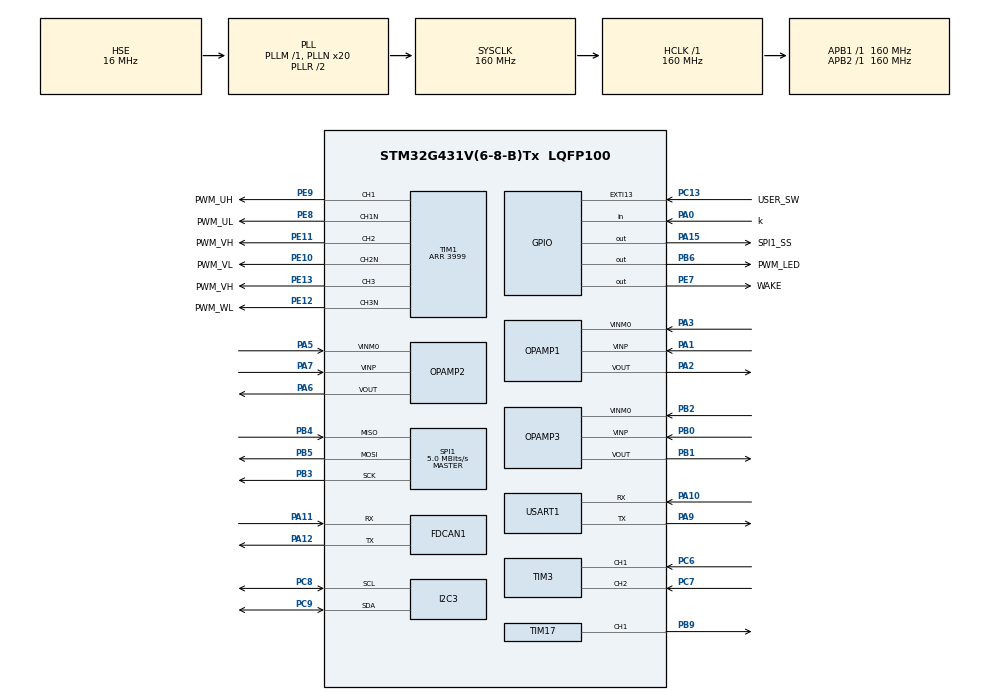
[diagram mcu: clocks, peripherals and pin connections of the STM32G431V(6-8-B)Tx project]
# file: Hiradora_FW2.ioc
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ADC1.ContinuousConvMode=ENABLE
ADC1.EnableInjectedConversion=ENABLE
ADC1.EnableRegularConversion=DISABLE
ADC1.ExternalTrigInjecConv=ADC_EXTERNALTRIGINJEC_T1_TRGO
ADC1.InjNumberOfConversion=3
ADC1.InjectedChannel-10\#ChannelInjectedConversion=ADC_CHANNEL_VREFINT
ADC1.InjectedChannel-6\#ChannelInjectedConversion=ADC_CHANNEL_3
ADC1.InjectedChannel-7\#ChannelInjectedConversion=ADC_CHANNEL_12
ADC1.InjectedOffsetNumber-10\#ChannelInjectedConversion=ADC_OFFSET_NONE
ADC1.InjectedOffsetNumber-6\#ChannelInjectedConversion=ADC_OFFSET_NONE
ADC1.InjectedOffsetNumber-7\#ChannelInjectedConversion=ADC_OFFSET_NONE
ADC1.InjectedRank-10\#ChannelInjectedConversion=3
ADC1.InjectedRank-6\#ChannelInjectedConversion=1
ADC1.InjectedRank-7\#ChannelInjectedConversion=2
ADC1.InjectedSamplingTime-10\#ChannelInjectedConversion=ADC_SAMPLETIME_2CYCLES_5
ADC1.InjectedSamplingTime-6\#ChannelInjectedConversion=ADC_SAMPLETIME_2CYCLES_5
ADC1.InjectedSamplingTime-7\#ChannelInjectedConversion=ADC_SAMPLETIME_2CYCLES_5
ADC1.Mode=ADC_DUALMODE_INJECSIMULT
ADC1.Rank1_Channel=ADC_CHANNEL_3
ADC1.Rank2_Channel=ADC_CHANNEL_12
ADC1.Rank3_Channel=ADC_CHANNEL_VREFINT
ADC1.master=1
ADC2.EnableInjectedConversion=ENABLE
ADC2.EnableRegularConversion=DISABLE
ADC2.InjNumberOfConversion=1
ADC2.InjectedChannel-19\#ChannelInjectedConversion=ADC_CHANNEL_3
ADC2.InjectedOffsetNumber-19\#ChannelInjectedConversion=ADC_OFFSET_NONE
ADC2.InjectedRank-19\#ChannelInjectedConversion=1
ADC2.InjectedSamplingTime-19\#ChannelInjectedConversion=ADC_SAMPLETIME_2CYCLES_5
ADC2.Mode=ADC_DUALMODE_INJECSIMULT
ADC2.Rank1_Channel=ADC_CHANNEL_3
Dma.Request0=SPI1_RX
Dma.SPI1_RX.0.Direction=DMA_PERIPH_TO_MEMORY
Dma.SPI1_RX.0.EventEnable=DISABLE
Dma.SPI1_RX.0.Instance=DMA1_Channel2
Dma.SPI1_RX.0.MemDataAlignment=DMA_MDATAALIGN_HALFWORD
Dma.SPI1_RX.0.MemInc=DMA_MINC_ENABLE
Dma.SPI1_RX.0.Mode=DMA_NORMAL
Dma.SPI1_RX.0.PeriphDataAlignment=DMA_PDATAALIGN_HALFWORD
Dma.SPI1_RX.0.PeriphInc=DMA_PINC_DISABLE
Dma.SPI1_RX.0.Polarity=HAL_DMAMUX_REQ_GEN_RISING
Dma.SPI1_RX.0.Priority=DMA_PRIORITY_VERY_HIGH
Dma.SPI1_RX.0.RequestNumber=1
Dma.SPI1_RX.0.SignalID=NONE
Dma.SPI1_RX.0.SyncEnable=DISABLE
Dma.SPI1_RX.0.SyncPolarity=HAL_DMAMUX_SYNC_NO_EVENT
Dma.SPI1_RX.0.SyncRequestNumber=1
Dma.SPI1_RX.0.SyncSignalID=NONE
FDCAN1.CalculateBaudRateNominal=1000000
FDCAN1.CalculateTimeBitNominal=1000
FDCAN1.CalculateTimeQuantumNominal=50.0
FDCAN1.DataPrescaler=2
FDCAN1.DataTimeSeg1=15
FDCAN1.DataTimeSeg2=4
FDCAN1.FrameFormat=FDCAN_FRAME_CLASSIC
FDCAN1.NominalPrescaler=8
FDCAN1.NominalTimeSeg1=15
FDCAN1.NominalTimeSeg2=4
FDCAN1.StdFiltersNbr=1
I2C3.Timing=0x30D29DE4
Mcu.Family=STM32G4
Mcu.Name=STM32G431V(6-8-B)Tx
Mcu.Package=LQFP100
NVIC.ADC1_2_IRQn=true\:0\:0\:true\:false\:true\:true\:true\:true
NVIC.DMA1_Channel2_IRQn=true\:0\:0\:false\:false\:true\:false\:true\:true
NVIC.EXTI15_10_IRQn=true\:0\:0\:false\:false\:true\:true\:true\:true
NVIC.FDCAN1_IT0_IRQn=true\:0\:0\:false\:false\:true\:true\:true\:true
NVIC.FDCAN1_IT1_IRQn=true\:0\:0\:false\:false\:true\:true\:true\:true
NVIC.PriorityGroup=NVIC_PRIORITYGROUP_4
NVIC.SPI1_IRQn=true\:0\:0\:false\:false\:true\:true\:true\:true
NVIC.TIM1_TRG_COM_TIM17_IRQn=true\:0\:0\:false\:false\:true\:true\:true\:true
NVIC.TIM1_UP_TIM16_IRQn=true\:0\:0\:true\:false\:true\:true\:true\:true
NVIC.TIM2_IRQn=true\:0\:0\:false\:false\:true\:true\:true\:true
NVIC.TIM3_IRQn=true\:0\:0\:false\:false\:true\:true\:true\:true
OPAMP1.PgaGain=OPAMP_PGA_GAIN_16_OR_MINUS_15
OPAMP1.PowerMode=OPAMP_POWERMODE_NORMALSPEED
OPAMP2.PgaGain=OPAMP_PGA_GAIN_16_OR_MINUS_15
OPAMP2.PowerMode=OPAMP_POWERMODE_NORMALSPEED
OPAMP3.PgaGain=OPAMP_PGA_GAIN_16_OR_MINUS_15
OPAMP3.PowerMode=OPAMP_POWERMODE_NORMALSPEED
PA0.GPIO_Label=k
PA0.Signal=GPIO_Input
PA1.Mode=PGA Connected-INVERTINGINPUT_IO0_BIAS
PA1.Signal=OPAMP1_VINP
PA10.Mode=Asynchronous
PA10.Signal=USART1_RX
PA11.Mode=FDCAN_Activate
PA11.Signal=FDCAN1_RX
PA12.Mode=FDCAN_Activate
PA12.Signal=FDCAN1_TX
PA15.GPIO_Label=SPI1_SS
PA15.GPIO_Speed=GPIO_SPEED_FREQ_VERY_HIGH
PA15.Signal=GPIO_Output
PA2.Signal=SharedAnalog_PA2
PA3.Mode=PGA Connected-INVERTINGINPUT_IO0_BIAS
PA3.Signal=OPAMP1_VINM0
PA5.Mode=PGA Connected-INVERTINGINPUT_IO0_BIAS
PA5.Signal=OPAMP2_VINM0
PA6.Signal=SharedAnalog_PA6
PA7.Mode=PGA Connected-INVERTINGINPUT_IO0_BIAS
PA7.Signal=OPAMP2_VINP
PA9.Mode=Asynchronous
PA9.Signal=USART1_TX
PB0.Mode=PGA Connected-INVERTINGINPUT_IO0_BIAS
PB0.Signal=OPAMP3_VINP
PB1.Signal=SharedAnalog_PB1
PB2.Mode=PGA Connected-INVERTINGINPUT_IO0_BIAS
PB2.Signal=OPAMP3_VINM0
PB3.Mode=Full_Duplex_Master
PB3.Signal=SPI1_SCK
PB4.Mode=Full_Duplex_Master
PB4.Signal=SPI1_MISO
PB5.Mode=Full_Duplex_Master
PB5.Signal=SPI1_MOSI
PB6.GPIO_Label=PWM_LED
PB6.Signal=GPIO_Output
PB9.Signal=S_TIM17_CH1
PC13.GPIO_Label=USER_SW
PC13.GPIO_ModeDefaultEXTI=GPIO_MODE_IT_FALLING
PC13.Signal=GPXTI13
PC6.Signal=S_TIM3_CH1
PC7.Signal=S_TIM3_CH2
PC8.Mode=I2C
PC8.Signal=I2C3_SCL
PC9.Mode=I2C
PC9.Signal=I2C3_SDA
PE10.GPIO_Label=PWM_VL
PE10.Mode=PWM Generation2 CH2 CH2N
PE10.Signal=TIM1_CH2N
PE11.GPIO_Label=PWM_VH
PE11.Signal=S_TIM1_CH2
PE12.GPIO_Label=PWM_WL
PE12.Mode=PWM Generation3 CH3 CH3N
PE12.Signal=TIM1_CH3N
PE13.GPIO_Label=PWM_VH
PE13.Signal=S_TIM1_CH3
PE7.GPIO_Label=WAKE
PE7.Signal=GPIO_Output
PE8.GPIO_Label=PWM_UL
PE8.Mode=PWM Generation1 CH1 CH1N
PE8.Signal=TIM1_CH1N
PE9.GPIO_Label=PWM_UH
PE9.Signal=S_TIM1_CH1
PF0-OSC_IN.Mode=HSE-External-Oscillator
PF0-OSC_IN.Signal=RCC_OSC_IN
PF1-OSC_OUT.Mode=HSE-External-Oscillator
PF1-OSC_OUT.Signal=RCC_OSC_OUT
ProjectManager.HeapSize=0x200
ProjectManager.StackSize=0xc00
ProjectManager.TargetToolchain=CMake
RCC.ADC12Freq_Value=160000000
RCC.AHBFreq_Value=160000000
RCC.APB1Freq_Value=160000000
RCC.APB1TimFreq_Value=160000000
RCC.APB2Freq_Value=160000000
RCC.APB2TimFreq_Value=160000000
RCC.CortexFreq_Value=160000000
RCC.EXTERNAL_CLOCK_VALUE=12288000
RCC.HCLKFreq_Value=160000000
RCC.HSE_VALUE=16000000
RCC.HSI48_VALUE=48000000
RCC.HSI_VALUE=16000000
RCC.LSE_VALUE=32768
RCC.PLLN=20
RCC.PLLSourceVirtual=RCC_PLLSOURCE_HSE
RCC.SYSCLKFreq_VALUE=160000000
RCC.SYSCLKSource=RCC_SYSCLKSOURCE_PLLCLK
RCC.USBFreq_Value=160000000
RCC.VCOOutputFreq_Value=320000000
SH.S_TIM17_CH1.0=TIM17_CH1,PWM Generation1 CH1
SH.S_TIM1_CH1.0=TIM1_CH1,PWM Generation1 CH1 CH1N
SH.S_TIM1_CH2.0=TIM1_CH2,PWM Generation2 CH2 CH2N
SH.S_TIM1_CH3.0=TIM1_CH3,PWM Generation3 CH3 CH3N
SH.S_TIM3_CH1.0=TIM3_CH1,Encoder_Interface
SH.S_TIM3_CH2.0=TIM3_CH2,Encoder_Interface
SH.SharedAnalog_PA2.0=OPAMP1_VOUT,PGA Connected-INVERTINGINPUT_IO0_BIAS
SH.SharedAnalog_PA2.1=ADC1_IN3,IN3-Single-Ended
SH.SharedAnalog_PA6.0=OPAMP2_VOUT,PGA Connected-INVERTINGINPUT_IO0_BIAS
SH.SharedAnalog_PA6.1=ADC2_IN3,IN3-Single-Ended
SH.SharedAnalog_PB1.0=OPAMP3_VOUT,PGA Connected-INVERTINGINPUT_IO0_BIAS
SH.SharedAnalog_PB1.1=ADC1_IN12,IN12-Single-Ended
SPI1.BaudRatePrescaler=SPI_BAUDRATEPRESCALER_32
SPI1.CLKPhase=SPI_PHASE_2EDGE
SPI1.CalculateBaudRate=5.0 MBits/s
SPI1.DataSize=SPI_DATASIZE_16BIT
SPI1.Direction=SPI_DIRECTION_2LINES
SPI1.Mode=SPI_MODE_MASTER
SPI1.VirtualType=VM_MASTER
TIM1.AutoReloadPreload=TIM_AUTORELOAD_PRELOAD_ENABLE
TIM1.Channel-PWM\ Generation1\ CH1\ CH1N=TIM_CHANNEL_1
TIM1.Channel-PWM\ Generation2\ CH2\ CH2N=TIM_CHANNEL_2
TIM1.Channel-PWM\ Generation3\ CH3\ CH3N=TIM_CHANNEL_3
TIM1.CounterMode=TIM_COUNTERMODE_CENTERALIGNED3
TIM1.DeadTime=100
TIM1.DeadTimePreload=DISABLE
TIM1.OCFastMode_PWM-PWM\ Generation1\ CH1\ CH1N=TIM_OCFAST_DISABLE
TIM1.OCFastMode_PWM-PWM\ Generation2\ CH2\ CH2N=TIM_OCFAST_DISABLE
TIM1.OCFastMode_PWM-PWM\ Generation3\ CH3\ CH3N=TIM_OCFAST_DISABLE
TIM1.OCMode_PWM-PWM\ Generation1\ CH1\ CH1N=TIM_OCMODE_PWM2
TIM1.OCMode_PWM-PWM\ Generation2\ CH2\ CH2N=TIM_OCMODE_PWM2
TIM1.OCMode_PWM-PWM\ Generation3\ CH3\ CH3N=TIM_OCMODE_PWM2
TIM1.PeriodNoDither=3999
TIM1.RepetitionCounter=1
TIM1.TIM_MasterOutputTrigger=TIM_TRGO_UPDATE
TIM16.PeriodNoDither=15999
TIM16.Prescaler=99
TIM17.Channel=TIM_CHANNEL_1
TIM17.Prescaler=159
TIM2.PeriodNoDither=199
TIM2.Prescaler=159
TIM3.EncoderMode=TIM_ENCODERMODE_TI12
TIM8.PeriodNoDither=64
USART1.VirtualMode-Asynchronous=VM_ASYNC
VP_ADC1_Vref_Input.Mode=IN-Vrefint
VP_SYS_VS_DBSignals.Mode=DisableDeadBatterySignals
VP_TIM16_VS_ClockSourceINT.Mode=Enable_Timer
VP_TIM17_VS_ClockSourceINT.Mode=Enable_Timer
VP_TIM1_VS_ClockSourceINT.Mode=Internal
VP_TIM2_VS_ClockSourceINT.Mode=Internal
VP_TIM8_VS_ClockSourceINT.Mode=Internal
VP_TIM8_VS_OPM.Mode=OPM_bit
board=custom

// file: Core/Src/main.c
/* USER CODE BEGIN Header */
/**
  ******************************************************************************
  * @file           : main.c
  * @brief          : Main program body
  ******************************************************************************
  * @attention
  *
  * Copyright (c) 2026 STMicroelectronics.
  * All rights reserved.
  *
  * This software is licensed under terms that can be found in the LICENSE file
  * in the root directory of this software component.
  * If no LICENSE file comes \with this software, it is provided AS-IS.
  *
  ******************************************************************************
  */
/* USER CODE END Header */
#include "main.h"

/* USER CODE BEGIN Includes */
#include <stdint.h>
#include <stdio.h>
#include <string.h>
#include <math.h>
#include <stdlib.h>
/* USER CODE END Includes */

/* USER CODE BEGIN PTD */
typedef struct {
    volatile float speed;
    float p,i,d;
    volatile float speed_target;
    volatile float now_speed_target;
    volatile float different_sum;
    volatile float low_pass_different_sum;
    volatile float last_difference;
    volatile float last_input;
    volatile float low_pass_derivative;
    volatile float last_last_difference;
    volatile float current_d;
    volatile float current_p;
    volatile float current_d_target;
    volatile float current_p_target;
    volatile float current_d_different_sum;
    volatile float current_d_low_pass_different_sum;
    volatile float current_d_last_difference;      //currentは電流といういみ　現在ではない
    volatile float current_p_different_sum;
    volatile float current_p_low_pass_different_sum;
    volatile float current_p_last_difference;
    volatile float current_d_pgain;
    volatile float current_d_igain;
    volatile float current_d_dgain;
    volatile float current_p_pgain;
    volatile float current_p_igain;
    volatile float current_p_dgain;
}pid_items;

pid_items motor[3];

volatile int cutoff;
/* USER CODE END PTD */

/* USER CODE BEGIN PD */
#define CALIB_FLASH_ADDR   0x0801F800u
#define CALIB_MAGIC        0xCA11B0A1u

typedef struct __attribute__((packed)) {
    uint32_t magic;
    float    zero_offset_rad;
    uint32_t crc;
} calib_data_t;
/* USER CODE END PD */

ADC_HandleTypeDef hadc1;
ADC_HandleTypeDef hadc2;

FDCAN_HandleTypeDef hfdcan1;

I2C_HandleTypeDef hi2c3;

OPAMP_HandleTypeDef hopamp1;
OPAMP_HandleTypeDef hopamp2;
OPAMP_HandleTypeDef hopamp3;

SPI_HandleTypeDef hspi1;
DMA_HandleTypeDef hdma_spi1_rx;

TIM_HandleTypeDef htim1;
TIM_HandleTypeDef htim2;
TIM_HandleTypeDef htim3;
TIM_HandleTypeDef htim8;
TIM_HandleTypeDef htim16;
TIM_HandleTypeDef htim17;

UART_HandleTypeDef huart1;

/* USER CODE BEGIN PV */

#define STSPIN_I2C_ADDR   (0x47 << 1)   // I2Cのスレーブアドレスには7bitアドレスと8bitアドレスがあり、アドレスの後ろに読み込みか書き込みかを示す1bit（R/Wビット）がくっついて送信される。

static HAL_StatusTypeDef stspin_write_reg(uint8_t reg, uint8_t val)
{
    return HAL_I2C_Mem_Write(&hi2c3, STSPIN_I2C_ADDR, reg,
                              I2C_MEMADD_SIZE_8BIT, &val, 1, 100);
}

static HAL_StatusTypeDef stspin_read_reg(uint8_t reg, uint8_t *val)
{
    return HAL_I2C_Mem_Read(&hi2c3, STSPIN_I2C_ADDR, reg,
                             I2C_MEMADD_SIZE_8BIT, val, 1, 100);
}

// STATUSレジスタ(0x80)を読み、フォルトがあればCLEAR(0x09)に0xFFを書く
static uint8_t stspin_clear_faults(void)
{
    uint8_t status = 0;
    stspin_read_reg(0x80, &status);
    if (status & 0x0F) {          // もしstatusの下位4bitの中に1があり、エラーがある場合はifが通る
        stspin_write_reg(0x09, 0xFF);  // CLEARレジスタ
    }
    return status;
}

#define PWM_PERIOD 3999      //カウンターがどこまで数えたら 0 に戻るかを決める天井の数値
#define POLE_PAIRS 7         //モーターの外側についている磁石の数
#define clock_time 0.0002    //time一回当たりの周期
#define resistance_for_current 0.001   //電流計測に用いる抵抗値
#define opamp_gain 16.0  //cudemxで設定したPGAgainの値
#define MAX_PHASE_CURRENT_A   7.0f
#define drive_voltage 3.3  //マイコンの駆動電圧
static inline float fast_sin(float x) { return sinf(x); }
static inline float fast_cos(float x) { return cosf(x); }

volatile int pid_mode[3] = {0, 0, 0};   //0ならlocate_pid 1ならspeed_pid
volatile int control_motor_mode[3] = {0, 0, 0};       //モーターの制御モード

volatile uint32_t rx_ok_count = 0;
static volatile uint32_t tim2_cnt = 0;

/*電流値　単位はアンペア*/
volatile float current_u = 0.0f;
volatile float current_v = 0.0f;
volatile float current_w = 0.0f;
volatile uint8_t overcurrent_fault = 0;

//現在の速度を計算する？ための関数
volatile float speed_now = 0;

/*実際にADCで読み取った値*/
uint32_t offset_u = 2048;
uint32_t offset_v = 2048;
uint32_t offset_w = 2048;

#define CAN_MOTOR_CMD_BASE_ID  0x303u
#define CAN_MOTOR_NUM          3u

typedef struct __attribute__((packed)) {
    float   speed_target;         /* byte0-3 */
    uint8_t pid_mode;             /* byte4: 0=locate_pid, 1=speed_pid */
    uint8_t control_motor_mode;   /* byte5: 0=電圧制御, 1=電流制御 */
    uint8_t reserved[2];          /* byte6-7 */
} can_motor_cmd_t;

/* USER CODE END PV */

void SystemClock_Config(void);
static void MX_GPIO_Init(void);
static void MX_DMA_Init(void);
static void MX_TIM1_Init(void);
static void MX_FDCAN1_Init(void);
static void MX_SPI1_Init(void);
static void MX_TIM17_Init(void);
static void MX_USART1_UART_Init(void);
static void MX_I2C3_Init(void);
static void MX_TIM2_Init(void);
static void MX_TIM16_Init(void);
static void MX_ADC1_Init(void);
static void MX_ADC2_Init(void);
static void MX_OPAMP1_Init(void);
static void MX_OPAMP2_Init(void);
static void MX_OPAMP3_Init(void);
static void MX_TIM8_Init(void);
static void MX_TIM3_Init(void);
/* USER CODE BEGIN PFP */
float locate_pid(volatile float output, float target, float p, float i, float d,volatile float *different_sum, volatile float *low_pass_different_sum,volatile float *last_difference, int cutoff);
float speed_pid(volatile float output, float target, float p, float i, float d, volatile float *low_pass_different_sum, volatile float *last_difference, volatile float *last_last_difference, volatile float last_input, volatile float *low_pass_derivative, int cutoff);
void measure_current(void);
static void FDCAN1_ConfigFilterAndStart(void);
static int calib_load(float *zero_offset_rad_out);
static HAL_StatusTypeDef calib_save(float zero_offset_rad_val);
/* USER CODE END PFP */

/* USER CODE BEGIN 0 */

static void FDCAN1_ConfigFilterAndStart(void)
{
    FDCAN_FilterTypeDef sFilterConfig;

    /* 0x301〜0x303 の標準IDだけをRXFIFO0に通す */
    sFilterConfig.IdType       = FDCAN_STANDARD_ID;
    sFilterConfig.FilterIndex  = 0;
    sFilterConfig.FilterType   = FDCAN_FILTER_DUAL;
    sFilterConfig.FilterConfig = FDCAN_FILTER_TO_RXFIFO0;
    sFilterConfig.FilterID1    = CAN_MOTOR_CMD_BASE_ID;
    sFilterConfig.FilterID2    = CAN_MOTOR_CMD_BASE_ID;
    if (HAL_FDCAN_ConfigFilter(&hfdcan1, &sFilterConfig) != HAL_OK)
    {
        Error_Handler();
    }

    /* フィルタに合致しないフレームは破棄、リモートフレームも破棄 */
    if (HAL_FDCAN_ConfigGlobalFilter(&hfdcan1, FDCAN_REJECT, FDCAN_REJECT,
                                      FDCAN_FILTER_REMOTE, FDCAN_FILTER_REMOTE) != HAL_OK)
    {
        Error_Handler();
    }

    if (HAL_FDCAN_ActivateNotification(&hfdcan1, FDCAN_IT_RX_FIFO0_NEW_MESSAGE, 0) != HAL_OK)
    {
        Error_Handler();
    }

    if (HAL_FDCAN_Start(&hfdcan1) != HAL_OK)
    {
        Error_Handler();
    }
}

void HAL_FDCAN_RxFifo0Callback(FDCAN_HandleTypeDef *hfdcan, uint32_t RxFifo0ITs)
{
    if ((RxFifo0ITs & FDCAN_IT_RX_FIFO0_NEW_MESSAGE) == 0) return;

    FDCAN_RxHeaderTypeDef RxHeader;
    uint8_t RxData[8];

    if (HAL_FDCAN_GetRxMessage(hfdcan, FDCAN_RX_FIFO0, &RxHeader, RxData) != HAL_OK)
    {
        return;
    }

    if (RxHeader.IdType != FDCAN_STANDARD_ID) return;
    if (RxHeader.DataLength != FDCAN_DLC_BYTES_8) return;
    can_motor_cmd_t cmd;
    memcpy(&cmd, RxData, sizeof(cmd));

    /* 範囲外の値でモーターが暴走しないよう軽くクリップ */
    if (cmd.speed_target > 5000.0f)  cmd.speed_target = 5000.0f;
    if (cmd.speed_target < -5000.0f) cmd.speed_target = -5000.0f;

    /* 0x301/0x302/0x303どれで来ても、この基板はmotor[0]固定 */
    motor[0].speed_target       = cmd.speed_target;
    pid_mode[0]                 = cmd.pid_mode ? 1 : 0;
    control_motor_mode[0]       = cmd.control_motor_mode ? 1 : 0;

    rx_ok_count++;
}

static uint16_t spi_transfer_16(uint16_t tx)
{
    uint16_t rx = 0;

    HAL_GPIO_WritePin(SPI1_SS_GPIO_Port, SPI1_SS_Pin, GPIO_PIN_RESET);// 通信開始
    HAL_SPI_TransmitReceive(&hspi1, (uint8_t*)&tx, (uint8_t*)&rx, 1, HAL_MAX_DELAY);// 16ビット送受信
    HAL_GPIO_WritePin(SPI1_SS_GPIO_Port, SPI1_SS_Pin, GPIO_PIN_SET); // 通信終了

    return rx;
}

uint16_t as5047p_read_angle(void)
{

    spi_transfer_16(0xFFFF);   // 1回目に返ってくるデータはゴミ
    uint16_t raw = spi_transfer_16(0xC000); // 2回目には何もしない空データを送り、その隙に1回目で要求したデータを受け取る
    return raw & 0x3FFF;    // 余計なビットを消して、純粋な14ビットデータにする

}

int _write(int file, char *ptr, int len)
{
  (void)file;
  HAL_UART_Transmit(&huart1, (uint8_t*)ptr, (uint16_t)len, HAL_MAX_DELAY);
  return len;

}

void set_pwm(float ua, float ub, float uc)
{

    /*各相の電圧指令値は0から1であるので不正な値を消去*/
    if (ua < 0.0f) ua = 0.0f;
    if (ua > 1.0f) ua = 1.0f;
    if (ub < 0.0f) ub = 0.0f;
    if (ub > 1.0f) ub = 1.0f;
    if (uc < 0.0f) uc = 0.0f;
    if (uc > 1.0f) uc = 1.0f;

    /*CCRがCNT(0からPWM_PERIODまでの高速カウント)より大きい時low、それ以外はhighとなる*/
    TIM1->CCR1 = (uint32_t)(ua * PWM_PERIOD);
    TIM1->CCR2 = (uint32_t)(ub * PWM_PERIOD);
    TIM1->CCR3 = (uint32_t)(uc * PWM_PERIOD);
}

static float electrical_direction = 0.0f;
static float step_move = 0.01f;      //使っていないが残している
static float amp = 0.05f;           // 出力の大きさを調整できる
static float zero_offset_rad = 0.0f;  //初期位置のずれを確認する

/*while表示用*/
uint16_t diag;
float angle_deg;
uint16_t angle_raw;
float speed_rpm;
int32_t speed_rpm_int;

void update_openloop(float voltage)
{

    static uint16_t prev_angle_raw = 0;
    static float filtered_speed = 0.0;
    static int speed_calc_cnt = 0;
    static uint16_t angle_at_last_calc = 0;

    angle_raw = as5047p_read_angle();

    float angle_mech = ((float)angle_raw / 16384.0f) * 2.0f * M_PI;
    static float motor_direction = 1.0f;
    electrical_direction = (angle_mech - zero_offset_rad) * POLE_PAIRS * motor_direction;

    // 速度計算は25回に1回(5ms間隔)だけ行う
    speed_calc_cnt++;
    if (speed_calc_cnt >= 25) {
        speed_calc_cnt = 0;
        int16_t diff = (int16_t)angle_raw - (int16_t)angle_at_last_calc;
        if (diff > 8192)  diff -= 16384;
        if (diff < -8192) diff += 16384;
        angle_at_last_calc = angle_raw;

        speed_now = ((float)diff / 16384.0f) / (clock_time * 25.0f) * 60.0f;
        filtered_speed = filtered_speed * 0.7f + speed_now * 0.3f;
        motor[0].speed = filtered_speed;
    }

    float vd;
    float vq;
    /*速度制御*/
    if (control_motor_mode[0] == 0) {

      /*座標返還*/
      vd = 0.0f;
      vq = voltage;

    }

    /*電流制御*/
    if (control_motor_mode[0] == 1){
        vd = locate_pid(motor[0].current_d, motor[0].current_d_target, motor[0].current_d_pgain, motor[0].current_d_igain, motor[0].current_d_dgain, &motor[0].current_d_different_sum, &motor[0].current_d_low_pass_different_sum, &motor[0].current_d_last_difference, cutoff);
        vq = locate_pid(motor[0].current_p, motor[0].current_p_target, motor[0].current_p_pgain, motor[0].current_p_igain, motor[0].current_p_dgain, &motor[0].current_p_different_sum, &motor[0].current_p_low_pass_different_sum, &motor[0].current_p_last_difference, cutoff);

        if (vd > 0.3f)  vd = 0.3f;
        if (vd < -0.3f) vd = -0.3f;
        if (vq > 0.3f)  vq = 0.3f;
        if (vq < -0.3f) vq = -0.3f;

    }

    float va = vd * fast_cos(electrical_direction) - vq * fast_sin(electrical_direction);
    float vb = vd * fast_sin(electrical_direction) + vq * fast_cos(electrical_direction);

    float u = va;
    float v = -0.5f * va + 0.866f * vb;
    float w = -0.5f * va - 0.866f * vb;

    float offset = 0.5f;
    set_pwm(u + offset, v + offset, w + offset);

    /*意味ない*/
    electrical_direction += step_move;
    if (electrical_direction > 2.0f * M_PI) electrical_direction -= 2.0f * M_PI;
    /*ここまで*/
    // static int dbg_cnt = 0;
    // if (++dbg_cnt >= 50) {
    // dbg_cnt = 0;
    // printf("mode=%d vd=%d vq=%d elec_dir=%d enc=%u speed=%d\r\n",
    //    control_motor_mode[0], (int)(vd*1000), (int)(vq*1000),
    //    (int)(electrical_direction*1000), angle_raw, (int)motor[0].speed);
    //}
}

void HAL_TIM_PeriodElapsedCallback(TIM_HandleTypeDef *htim)
{

    if (htim->Instance == TIM2)
    {
        tim2_cnt++;
        /*意味ないここから(この部分があるからとはいえプログラムに変化はない)*/
        static uint32_t cnt = 0;

        if (++cnt >= 5000) {
          cnt = 0;
        }

        if (step_move < 0.010f) step_move +=  0.00001f;  // 速度
        if (amp < 0.05f) amp += 0.0000001f;               // トルク
        /*ここまで*/

        if (overcurrent_fault) {
            return;
        }

        /*最初電流差でがたがたいうので速度目標を少しずつ上げることで回避したい*/
        if (motor[0].speed_target == 0.0f) {
        /* 停止指令が来たら即座に目標速度を0にする(ドリフト防止) */
          motor[0].now_speed_target = 0.0f;
        } else if (motor[0].now_speed_target < motor[0].speed_target) {
          motor[0].now_speed_target += 0.5f;
          if (motor[0].now_speed_target > motor[0].speed_target) {
            motor[0].now_speed_target = motor[0].speed_target;
          }
        } else if (motor[0].now_speed_target > motor[0].speed_target) {
          motor[0].now_speed_target -= 0.5f;
          if (motor[0].now_speed_target < motor[0].speed_target) {
            motor[0].now_speed_target = motor[0].speed_target;
          }
        }

        float voltage_out = 0.0f;  // ← スコープを外に出す

        if (pid_mode[0] == 0) {
          voltage_out = locate_pid(motor[0].speed, motor[0].now_speed_target,
          motor[0].p, motor[0].i, motor[0].d,
          &motor[0].different_sum, &motor[0].low_pass_different_sum,
          &motor[0].last_difference, cutoff);
        }

        if (pid_mode[0] == 1) {
          voltage_out = speed_pid(
            motor[0].speed,
            motor[0].now_speed_target,
            motor[0].p,
            motor[0].i,
            motor[0].d,
            &motor[0].low_pass_different_sum,
            &motor[0].last_difference,
            &motor[0].last_last_difference,
            motor[0].last_input,
            &motor[0].low_pass_derivative,
            cutoff
    );
    motor[0].last_input = voltage_out;
        }

        // locate_pidとspeed_pidの出力は-16384〜16384なので0〜0.3にスケール変換
        float voltage = voltage_out / 16384.0f * 0.3f;

        update_openloop(voltage);

        //measure_current();   //電流測定
    }
}

/*pid(速度型ではない方)*/
float locate_pid(volatile float output, float target, float p, float i, float d, volatile float *different_sum, volatile float *low_pass_different_sum, volatile float *last_difference, int cutoff) {

  float input;
  float difference;
  float derivarate;

  difference = target - output;

  *different_sum += difference * clock_time;
  if (*different_sum > 1000) {
    *different_sum = 1000;
  }
  if (*different_sum < -1000) {
    *different_sum = -1000;
  }

  derivarate = difference - *last_difference;
  *low_pass_different_sum += (derivarate - *low_pass_different_sum) / (float)cutoff;  //ローパス

  if (*low_pass_different_sum > 1000.0) {
    *low_pass_different_sum = 1000;
  }
  if (*low_pass_different_sum < -1000.0) {
    *low_pass_different_sum = -1000.0;
  }

  input = p * difference + i * (*different_sum) + d * (*low_pass_different_sum);

  *last_difference = difference;

  if (input >= 16384) {
    input = 16384;
  }
  if (input <= -16384) {
    input = -16384;
  }

  return input;
  }

/*pid速度型*/
float speed_pid(volatile float output, float target, float p, float i, float d, volatile float *low_pass_different_sum, volatile float *last_difference, volatile float *last_last_difference, volatile float last_input, volatile float *low_pass_derivative, int cutoff) {
  float input;
  float difference;
  float derivarate;

  difference = target - output;
  derivarate = difference - 2 * *last_difference + *last_last_difference;
  *low_pass_derivative += (derivarate - *low_pass_derivative) / (float)cutoff;  //ローパス

  if (*low_pass_derivative > 1000.0) {
    *low_pass_derivative = 1000;
  }
  if (*low_pass_derivative < -1000.0) {
    *low_pass_derivative = -1000.0;
  }

  input = p * (difference - *last_difference) + i * (difference * clock_time) + d * *low_pass_derivative / clock_time;
  input += last_input;

  if (input >= 16384) {
    input = 16384;
  }
  if (input <= -16384) {
    input = -16384;
  }

  *last_last_difference = *last_difference;
  *last_difference = difference;

  return input;

}

void measure_current(void) {

  uint32_t raw_u = HAL_ADCEx_InjectedGetValue(&hadc1, ADC_INJECTED_RANK_1);
  uint32_t raw_w = HAL_ADCEx_InjectedGetValue(&hadc1, ADC_INJECTED_RANK_2);

  float magnification_conversion = (drive_voltage / 4096.0f) / (opamp_gain * resistance_for_current);

  current_u = ((float)raw_u - (float)offset_u) * magnification_conversion;
  current_w = ((float)raw_w - (float)offset_w) * magnification_conversion;
  current_v = -(current_u + current_w);

  /* ★ 過電流保護: 各相電流の絶対値が閾値を超えたら即座にPWM停止 */
  if (!overcurrent_fault &&
      (fabsf(current_u) > MAX_PHASE_CURRENT_A ||
       fabsf(current_v) > MAX_PHASE_CURRENT_A ||
       fabsf(current_w) > MAX_PHASE_CURRENT_A))
  {
      overcurrent_fault = 1;

      set_pwm(0.5f, 0.5f, 0.5f);   // デューティ50%(=出力ゼロ)にしてから停止

      HAL_TIM_PWM_Stop(&htim1, TIM_CHANNEL_1);
      HAL_TIMEx_PWMN_Stop(&htim1, TIM_CHANNEL_1);
      HAL_TIM_PWM_Stop(&htim1, TIM_CHANNEL_2);
      HAL_TIMEx_PWMN_Stop(&htim1, TIM_CHANNEL_2);
      HAL_TIM_PWM_Stop(&htim1, TIM_CHANNEL_3);
      HAL_TIMEx_PWMN_Stop(&htim1, TIM_CHANNEL_3);
  }

  // Clarke変換 (u,v,w → alpha,beta)
  float i_alpha = current_u;
  float i_beta  = (current_u + 2.0f * current_v) * 0.57735f;

  float id =  i_alpha * fast_cos(electrical_direction) + i_beta * fast_sin(electrical_direction);
  float iq = -i_alpha * fast_sin(electrical_direction) + i_beta * fast_cos(electrical_direction);

  motor[0].current_d = id;
  motor[0].current_p = iq;
}

void test_openloop_spin_veryslow(void)
{
    static float test_angle = 0.0f;
    float test_vq = 0.15f;

    test_angle += 0.0002f; // 0.0008 → 0.0002 にさらに減速(約1/4)
    if (test_angle > 2.0f*M_PI) test_angle -= 2.0f*M_PI;

    float va = -test_vq * fast_sin(test_angle);
    float vb =  test_vq * fast_cos(test_angle);
    float u = va;
    float v = -0.5f*va + 0.866f*vb;
    float w = -0.5f*va - 0.866f*vb;
    set_pwm(u+0.5f, v+0.5f, w+0.5f);

    uint16_t enc = as5047p_read_angle();
    static int log_cnt = 0;
    // if (++log_cnt >= 50) {
    //     log_cnt = 0;
    //     //printf("cmd_elec=%d enc=%u\r\n", (int)(test_angle*1000), enc);
    // }
}

static uint32_t calib_simple_crc(uint32_t magic, float val)
{
    uint32_t v;
    memcpy(&v, &val, sizeof(v));
    return magic ^ v ^ 0xA5A5A5A5u;
}

static int calib_load(float *zero_offset_rad_out)
{
    const calib_data_t *stored = (const calib_data_t *)CALIB_FLASH_ADDR;

    if (stored->magic != CALIB_MAGIC) {
        return 0;
    }
    uint32_t expect_crc = calib_simple_crc(stored->magic, stored->zero_offset_rad);
    if (stored->crc != expect_crc) {
        return 0;
    }

    *zero_offset_rad_out = stored->zero_offset_rad;
    return 1;
}

static HAL_StatusTypeDef calib_save(float zero_offset_rad_val)
{
    calib_data_t data;
    data.magic = CALIB_MAGIC;
    data.zero_offset_rad = zero_offset_rad_val;
    data.crc = calib_simple_crc(data.magic, data.zero_offset_rad);

    HAL_FLASH_Unlock();

    FLASH_EraseInitTypeDef erase = {0};
    uint32_t page_error = 0;
    erase.TypeErase = FLASH_TYPEERASE_PAGES;
    erase.Banks     = FLASH_BANK_1;
    erase.Page      = (CALIB_FLASH_ADDR - FLASH_BASE) / FLASH_PAGE_SIZE;
    erase.NbPages   = 1;

    HAL_StatusTypeDef st = HAL_FLASHEx_Erase(&erase, &page_error);
    if (st != HAL_OK) {
        HAL_FLASH_Lock();
        return st;
    }

    uint64_t buf[2] = {0};
    memcpy(buf, &data, sizeof(data));   // 12byte分をコピー、残りは0埋め

    uint32_t addr = CALIB_FLASH_ADDR;
    for (int i = 0; i < 2; i++) {
        st = HAL_FLASH_Program(FLASH_TYPEPROGRAM_DOUBLEWORD, addr + i * 8, buf[i]);
        if (st != HAL_OK) break;
    }

    HAL_FLASH_Lock();
    return st;
}

/* USER CODE END 0 */

int main(void)
{

  /* MCU Configuration--------------------------------------------------------*/

  /* Reset of all peripherals, Initializes the Flash interface and the Systick. */
  HAL_Init();

  /* Configure the system clock */
  SystemClock_Config();

  /* Initialize all configured peripherals */
  MX_GPIO_Init();
  MX_DMA_Init();
  MX_TIM1_Init();
  MX_FDCAN1_Init();
  MX_SPI1_Init();
  MX_TIM17_Init();
  MX_USART1_UART_Init();
  MX_I2C3_Init();
  MX_TIM2_Init();
  MX_TIM16_Init();
  MX_ADC1_Init();
  MX_ADC2_Init();
  MX_OPAMP1_Init();
  MX_OPAMP2_Init();
  MX_OPAMP3_Init();
  MX_TIM8_Init();
  MX_TIM3_Init();
  /* USER CODE BEGIN 2 */
  printf("step1: peripherals init done\r\n");
  for(int i=0;i<3;i++){
    motor[i].speed=0.0;
    motor[i].speed_target=0.0;
    if (pid_mode[i] == 0) {
      //n2830
      //motor[i].p=37.0;
      //motor[i].i=2.0;
      //motor[i].d=1.4;
      //n5065
      if(control_motor_mode[i] == 0){
        motor[i].p=35;
        motor[i].i=1.8;
        motor[i].d=1.4;
      }
      if(control_motor_mode[i] == 1){
        motor[i].current_d_pgain = 0.0;
        motor[i].current_d_igain = 0.0;
        motor[i].current_d_dgain = 0.0;
        motor[i].current_p_pgain = 0.0;
        motor[i].current_p_igain = 0.0;
        motor[i].current_p_dgain = 0.0;
      }
    }
    if (pid_mode[i] == 1) {
      if(control_motor_mode[i] == 0){
      motor[i].p=1.0;
      motor[i].i=0.05;
      motor[i].d=0.0;
      }
      if(control_motor_mode[i] == 1){
        motor[i].current_d_pgain = 0.0;
        motor[i].current_d_igain = 0.0;
        motor[i].current_d_dgain = 0.0;
        motor[i].current_p_pgain = 0.0;
        motor[i].current_p_igain = 0.0;
        motor[i].current_p_dgain = 0.0;
      }
    }
    motor[i].now_speed_target = 0.0;
    motor[i].different_sum = 0.0;
    motor[i].low_pass_different_sum = 0.0;
    motor[i].last_difference = 0.0;
    motor[i].last_input = 0.0;
    motor[i].low_pass_derivative = 0.0;
    motor[i].last_last_difference = 0.0;
    motor[i].current_d = 0.0;
    motor[i].current_p = 0.0;
    motor[i].current_d_target = 0.0;
    motor[i].current_p_target = 0.0;
    motor[i].current_d_different_sum = 0.0;
    motor[i].current_d_low_pass_different_sum = 0.0;
    motor[i].current_d_last_difference = 0.0;      //currentは電流といういみ　現在ではない
    motor[i].current_p_different_sum = 0.0;
    motor[i].current_p_low_pass_different_sum = 0.0;
    motor[i].current_p_last_difference = 0.0;
  }
  cutoff = 8;

  printf("step2: motor struct init done\r\n");

  HAL_GPIO_WritePin(SPI1_SS_GPIO_Port, SPI1_SS_Pin, GPIO_PIN_SET);
  //エンコーダ―起動
  HAL_TIM_Encoder_Start(&htim3, TIM_CHANNEL_ALL);
  // WAKEピンでドライバ起動
  HAL_GPIO_WritePin(WAKE_GPIO_Port, WAKE_Pin, GPIO_PIN_SET);
  HAL_Delay(100);

  printf("step3: encoder + WAKE done\r\n");

  HAL_Delay(5);
  stspin_clear_faults();
  HAL_Delay(5);
  stspin_clear_faults();   // 念のため2回

  printf("step4: stspin faults cleared\r\n");

  // PWM出力開始
  HAL_TIM_PWM_Start(&htim1, TIM_CHANNEL_1);
  HAL_TIMEx_PWMN_Start(&htim1, TIM_CHANNEL_1);
  HAL_TIM_PWM_Start(&htim1, TIM_CHANNEL_2);
  HAL_TIMEx_PWMN_Start(&htim1, TIM_CHANNEL_2);
  HAL_TIM_PWM_Start(&htim1, TIM_CHANNEL_3);
  HAL_TIMEx_PWMN_Start(&htim1, TIM_CHANNEL_3);

  printf("step5: PWM started\r\n");

  //ADCキャリブレーション＆スタート
  HAL_ADCEx_Calibration_Start(&hadc1, ADC_SINGLE_ENDED);
  HAL_ADCEx_Calibration_Start(&hadc2, ADC_SINGLE_ENDED);

  printf("step6: ADC calibrated\r\n");

  // OPAMPスタート
  HAL_OPAMP_Start(&hopamp1);
  HAL_OPAMP_Start(&hopamp2);
  HAL_OPAMP_Start(&hopamp3);

  HAL_Delay(2);

  printf("step7: OPAMP started\r\n");

  //ADCキャリブレーション＆スタート
  // まずITなしでオフセット計測 オフセットを正確に行うため
  HAL_ADCEx_InjectedStart(&hadc1);
  HAL_ADCEx_InjectedStart(&hadc2);

  printf("step8: injected ADC started\r\n");

  /*offsetを計算するための変数*/
  uint32_t sum_u = 0.0;
  uint32_t sum_v = 0.0;
  uint32_t sum_w = 0.0;

  for (int i = 0; i < 100; i++) {
    HAL_Delay(1); // 少し待ってからADCのInjected変換結果を取得
    sum_u += HAL_ADCEx_InjectedGetValue(&hadc1, ADC_INJECTED_RANK_1);
    sum_v += HAL_ADCEx_InjectedGetValue(&hadc2, ADC_INJECTED_RANK_1);
    sum_w += HAL_ADCEx_InjectedGetValue(&hadc1, ADC_INJECTED_RANK_2);
  }

  offset_u = sum_u / 100;
  offset_v = sum_v / 100;
  offset_w = sum_w / 100;

  printf("Offset U:%lu, V:%lu, W:%lu\r\n", offset_u, offset_v, offset_w);
  printf("step9: offset measured U:%lu V:%lu W:%lu\r\n", offset_u, offset_v, offset_w);

  // オフセット計測後にIT版に切り替え ここから割り込みを行うことでoffsetにノイズがのることを防ぐ
  HAL_ADCEx_InjectedStop(&hadc1);
  HAL_ADCEx_InjectedStop(&hadc2);
  HAL_ADCEx_InjectedStart_IT(&hadc1);
  HAL_ADCEx_InjectedStart_IT(&hadc2);

  printf("step10: injected IT started\r\n");

  //FCO処理
  float loaded_zero_offset;
  if (calib_load(&loaded_zero_offset)) {
      zero_offset_rad = loaded_zero_offset;
      printf("step11: calibration loaded from flash, zero_offset_rad=%d\r\n",
             (int)(zero_offset_rad * 1000));
  } else {
      set_pwm(0.58f, 0.46f, 0.46f);
      HAL_Delay(1000); // U相に電圧をかけてモータを「0度」に強制ロック
               // 1秒待って完全に静止させる
      // その位置を「ゼロ点ズレ」として記憶
      zero_offset_rad = ((float)as5047p_read_angle() / 16384.0f) * 2.0f * M_PI;

      if (calib_save(zero_offset_rad) == HAL_OK) {
          printf("step11: FCO lock done, saved to flash, zero_offset_rad=%d\r\n",
                 (int)(zero_offset_rad * 1000));
      } else {
          printf("step11: FCO lock done, FLASH SAVE FAILED, zero_offset_rad=%d\r\n",
                 (int)(zero_offset_rad * 1000));
      }

      /* ロックが実際に効いているかの確認は、ロックした場合のみ実施 */
      uint16_t angle_before = as5047p_read_angle();
      HAL_Delay(200);
      uint16_t angle_after = as5047p_read_angle();
      int16_t diff = (int16_t)angle_after - (int16_t)angle_before;
      if (diff > 8192) diff -= 16384;
      if (diff < -8192) diff += 16384;
      if (abs(diff) > 50) { // ロック後も動いている＝ロック失敗
        printf("WARNING: FCO lock unstable! diff=%d\r\n", diff);
      }
  }
  // TIM2でコントロールループ開始（割り込み）
  HAL_NVIC_SetPriority(TIM2_IRQn, 1, 0);
  HAL_NVIC_EnableIRQ(TIM2_IRQn);

  HAL_NVIC_SetPriority(FDCAN1_IT0_IRQn, 0, 0);
  HAL_NVIC_SetPriority(TIM2_IRQn, 2, 0);

  HAL_TIM_Base_Start_IT(&htim2);
  setvbuf(stdout, NULL, _IONBF, 0);
  printf("boot\r\n");
  printf("boot: control loop started\r\n");
  //uint16_t prev_angle_raw = as5047p_read_angle();
  /* USER CODE END 2 */

  /* Infinite loop */
  /* USER CODE BEGIN WHILE */
  while (1)
  {
    static uint32_t fault_check_cnt = 0;
    if (++fault_check_cnt >= 5) {   // 200ms×5=1秒ごとくらいでもOK。もっと頻繁でも良い
        fault_check_cnt = 0;
        uint8_t st = stspin_clear_faults();
        if (st & 0x04) {
            printf("VDS protection tripped! cleared.\r\n");
        }
        if (st & 0x08) {
            printf("Device RESET detected! cleared.\r\n");
        }
    }

    fflush(stdout);
    HAL_Delay(200);
    /* USER CODE END WHILE */

    /* USER CODE BEGIN 3 */

    //printf("speed=%d rpm, target=%d rpm\r\n",(int32_t)motor[0].speed,(int32_t)motor[0].speed_target);
    //uint32_t display_deg = (uint32_t)((float)angle_raw * 360.0f / 16384.0f);
    //HAL_Delay(200);

    // spi_transfer_16(0xFFFC | 0x4000);   //1回目のごみ
    // diag = spi_transfer_16(0xC000);  //0xc000でエラー確認
    // printf("DIAG=0x%04X ", diag);
    // angle_raw = as5047p_read_angle();   //角度取得
    // angle_deg = angle_raw * 360.0f / 16384.0f;
    // printf("RAW=%u (%.1f deg) ", angle_raw, angle_deg);
    // int16_t diff = (int16_t)angle_raw - (int16_t)prev_angle_raw;
    // if (diff > 8192)  diff -= 16384; // 逆回転時の跨ぎ補正
    // if (diff < -8192) diff += 16384; // 正回転時の跨ぎ補正
    // prev_angle_raw = angle_raw;
    // float speed_rpm = ((float)diff / 16384.0f) / 0.2f * 60.0f;
    // printf("speed=%d rpm\r\n", (int32_t)speed_rpm);

    // fflush(stdout);
    // HAL_Delay(200);

    // すべて整数(%u や %d)で安全に出力
    //printf("RAW=%u (%u deg)\r\n", angle_raw, display_deg);
    // printf("spd=%d I_U=%d I_V=%d I_W=%d\n",
    // (int)(motor[0].speed),
    // (int)(current_u * 1000000),  // μA単位
    // (int)(current_v * 1000000),
    // (int)(current_w * 1000000));
    // fflush(stdout);
    // HAL_Delay(200);
    if (++fault_check_cnt >= 5) {
        fault_check_cnt = 0;
        uint8_t st = stspin_clear_faults();
        if (st & 0x04) printf("VDS protection tripped! cleared.\r\n");
        if (st & 0x08) printf("Device RESET detected! cleared.\r\n");
    }

    /* ★ 追加: CAN受信状況を表示 */
    FDCAN_ProtocolStatusTypeDef pstatus;
    FDCAN_ErrorCountersTypeDef  ecounters;
    HAL_FDCAN_GetProtocolStatus(&hfdcan1, &pstatus);
    HAL_FDCAN_GetErrorCounters(&hfdcan1, &ecounters);
    printf("rx_ok=%lu BusOff=%d ErrPassive=%d TEC=%lu REC=%lu target=%d tim2_cnt=%d pid_mode=%d ctrl_mode=%d speed=%d angle=%u OC_FAULT=%d I_U=%d I_V=%d I_W=%d\r\n",
   rx_ok_count, pstatus.BusOff, pstatus.ErrorPassive,
   (unsigned long)ecounters.TxErrorCnt, (unsigned long)ecounters.RxErrorCnt,
   (int)motor[0].speed_target, tim2_cnt,
   pid_mode[0], control_motor_mode[0],
   (int)motor[0].speed, angle_raw,
   overcurrent_fault,
   (int)(current_u*1000), (int)(current_v*1000), (int)(current_w*1000));
  }
  /* USER CODE END 3 */
}

void SystemClock_Config(void)
{
  RCC_OscInitTypeDef RCC_OscInitStruct = {0};
  RCC_ClkInitTypeDef RCC_ClkInitStruct = {0};

  /** Configure the main internal regulator output voltage
  */
  HAL_PWREx_ControlVoltageScaling(PWR_REGULATOR_VOLTAGE_SCALE1_BOOST);

  /** Initializes the RCC Oscillators according to the specified parameters
  * in the RCC_OscInitTypeDef structure.
  */
  RCC_OscInitStruct.OscillatorType = RCC_OSCILLATORTYPE_HSE;
  RCC_OscInitStruct.HSEState = RCC_HSE_ON;
  RCC_OscInitStruct.PLL.PLLState = RCC_PLL_ON;
  RCC_OscInitStruct.PLL.PLLSource = RCC_PLLSOURCE_HSE;
  RCC_OscInitStruct.PLL.PLLM = RCC_PLLM_DIV1;
  RCC_OscInitStruct.PLL.PLLN = 20;
  RCC_OscInitStruct.PLL.PLLP = RCC_PLLP_DIV2;
  RCC_OscInitStruct.PLL.PLLQ = RCC_PLLQ_DIV2;
  RCC_OscInitStruct.PLL.PLLR = RCC_PLLR_DIV2;
  if (HAL_RCC_OscConfig(&RCC_OscInitStruct) != HAL_OK)
  {
    Error_Handler();
  }

  /** Initializes the CPU, AHB and APB buses clocks
  */
  RCC_ClkInitStruct.ClockType = RCC_CLOCKTYPE_HCLK|RCC_CLOCKTYPE_SYSCLK
                              |RCC_CLOCKTYPE_PCLK1|RCC_CLOCKTYPE_PCLK2;
  RCC_ClkInitStruct.SYSCLKSource = RCC_SYSCLKSOURCE_PLLCLK;
  RCC_ClkInitStruct.AHBCLKDivider = RCC_SYSCLK_DIV1;
  RCC_ClkInitStruct.APB1CLKDivider = RCC_HCLK_DIV1;
  RCC_ClkInitStruct.APB2CLKDivider = RCC_HCLK_DIV1;

  if (HAL_RCC_ClockConfig(&RCC_ClkInitStruct, FLASH_LATENCY_4) != HAL_OK)
  {
    Error_Handler();
  }
}

static void MX_ADC1_Init(void)
{

  ADC_MultiModeTypeDef multimode = {0};
  ADC_InjectionConfTypeDef sConfigInjected = {0};

  /** Common config
  */
  hadc1.Instance = ADC1;
  hadc1.Init.ClockPrescaler = ADC_CLOCK_SYNC_PCLK_DIV4;
  hadc1.Init.Resolution = ADC_RESOLUTION_12B;
  hadc1.Init.DataAlign = ADC_DATAALIGN_RIGHT;
  hadc1.Init.GainCompensation = 0;
  hadc1.Init.ScanConvMode = ADC_SCAN_ENABLE;
  hadc1.Init.EOCSelection = ADC_EOC_SINGLE_CONV;
  hadc1.Init.LowPowerAutoWait = DISABLE;
  hadc1.Init.ContinuousConvMode = ENABLE;
  hadc1.Init.NbrOfConversion = 1;
  hadc1.Init.DiscontinuousConvMode = DISABLE;
  hadc1.Init.DMAContinuousRequests = DISABLE;
  hadc1.Init.Overrun = ADC_OVR_DATA_PRESERVED;
  hadc1.Init.OversamplingMode = DISABLE;
  if (HAL_ADC_Init(&hadc1) != HAL_OK)
  {
    Error_Handler();
  }

  /** Configure the ADC multi-mode
  */
  multimode.Mode = ADC_DUALMODE_INJECSIMULT;
  multimode.DMAAccessMode = ADC_DMAACCESSMODE_DISABLED;
  multimode.TwoSamplingDelay = ADC_TWOSAMPLINGDELAY_1CYCLE;
  if (HAL_ADCEx_MultiModeConfigChannel(&hadc1, &multimode) != HAL_OK)
  {
    Error_Handler();
  }

  /** Configure Injected Channel
  */
  sConfigInjected.InjectedChannel = ADC_CHANNEL_3;
  sConfigInjected.InjectedRank = ADC_INJECTED_RANK_1;
  sConfigInjected.InjectedSamplingTime = ADC_SAMPLETIME_2CYCLES_5;
  sConfigInjected.InjectedSingleDiff = ADC_SINGLE_ENDED;
  sConfigInjected.InjectedOffsetNumber = ADC_OFFSET_NONE;
  sConfigInjected.InjectedOffset = 0;
  sConfigInjected.InjectedNbrOfConversion = 3;
  sConfigInjected.InjectedDiscontinuousConvMode = DISABLE;
  sConfigInjected.AutoInjectedConv = DISABLE;
  sConfigInjected.QueueInjectedContext = DISABLE;
  sConfigInjected.ExternalTrigInjecConv = ADC_EXTERNALTRIGINJEC_T1_TRGO;
  sConfigInjected.ExternalTrigInjecConvEdge = ADC_EXTERNALTRIGINJECCONV_EDGE_RISING;
  sConfigInjected.InjecOversamplingMode = DISABLE;
  if (HAL_ADCEx_InjectedConfigChannel(&hadc1, &sConfigInjected) != HAL_OK)
  {
    Error_Handler();
  }

  /** Configure Injected Channel
  */
  sConfigInjected.InjectedChannel = ADC_CHANNEL_12;
  sConfigInjected.InjectedRank = ADC_INJECTED_RANK_2;
  if (HAL_ADCEx_InjectedConfigChannel(&hadc1, &sConfigInjected) != HAL_OK)
  {
    Error_Handler();
  }

  /** Configure Injected Channel
  */
  sConfigInjected.InjectedChannel = ADC_CHANNEL_VREFINT;
  sConfigInjected.InjectedRank = ADC_INJECTED_RANK_3;
  if (HAL_ADCEx_InjectedConfigChannel(&hadc1, &sConfigInjected) != HAL_OK)
  {
    Error_Handler();
  }

}

static void MX_ADC2_Init(void)
{

  ADC_InjectionConfTypeDef sConfigInjected = {0};

  /** Common config
  */
  hadc2.Instance = ADC2;
  hadc2.Init.ClockPrescaler = ADC_CLOCK_SYNC_PCLK_DIV4;
  hadc2.Init.Resolution = ADC_RESOLUTION_12B;
  hadc2.Init.DataAlign = ADC_DATAALIGN_RIGHT;
  hadc2.Init.GainCompensation = 0;
  hadc2.Init.ScanConvMode = ADC_SCAN_DISABLE;
  hadc2.Init.EOCSelection = ADC_EOC_SINGLE_CONV;
  hadc2.Init.LowPowerAutoWait = DISABLE;
  hadc2.Init.ContinuousConvMode = ENABLE;
  hadc2.Init.NbrOfConversion = 1;
  hadc2.Init.DiscontinuousConvMode = DISABLE;
  hadc2.Init.DMAContinuousRequests = DISABLE;
  hadc2.Init.Overrun = ADC_OVR_DATA_PRESERVED;
  hadc2.Init.OversamplingMode = DISABLE;
  if (HAL_ADC_Init(&hadc2) != HAL_OK)
  {
    Error_Handler();
  }

  /** Configure Injected Channel
  */
  sConfigInjected.InjectedChannel = ADC_CHANNEL_3;
  sConfigInjected.InjectedRank = ADC_INJECTED_RANK_1;
  sConfigInjected.InjectedSamplingTime = ADC_SAMPLETIME_2CYCLES_5;
  sConfigInjected.InjectedSingleDiff = ADC_SINGLE_ENDED;
  sConfigInjected.InjectedOffsetNumber = ADC_OFFSET_NONE;
  sConfigInjected.InjectedOffset = 0;
  sConfigInjected.InjectedNbrOfConversion = 1;
  sConfigInjected.InjectedDiscontinuousConvMode = DISABLE;
  sConfigInjected.AutoInjectedConv = DISABLE;
  sConfigInjected.QueueInjectedContext = DISABLE;
  sConfigInjected.InjecOversamplingMode = DISABLE;
  if (HAL_ADCEx_InjectedConfigChannel(&hadc2, &sConfigInjected) != HAL_OK)
  {
    Error_Handler();
  }

}

static void MX_FDCAN1_Init(void)
{

  hfdcan1.Instance = FDCAN1;
  hfdcan1.Init.ClockDivider = FDCAN_CLOCK_DIV1;
  hfdcan1.Init.FrameFormat = FDCAN_FRAME_CLASSIC;
  hfdcan1.Init.Mode = FDCAN_MODE_NORMAL;
  hfdcan1.Init.AutoRetransmission = DISABLE;
  hfdcan1.Init.TransmitPause = DISABLE;
  hfdcan1.Init.ProtocolException = DISABLE;
  hfdcan1.Init.NominalPrescaler = 8;
  hfdcan1.Init.NominalSyncJumpWidth = 1;
  hfdcan1.Init.NominalTimeSeg1 = 15;
  hfdcan1.Init.NominalTimeSeg2 = 4;
  hfdcan1.Init.DataPrescaler = 2;
  hfdcan1.Init.DataSyncJumpWidth = 1;
  hfdcan1.Init.DataTimeSeg1 = 15;
  hfdcan1.Init.DataTimeSeg2 = 4;
  hfdcan1.Init.StdFiltersNbr = 1;
  hfdcan1.Init.ExtFiltersNbr = 0;
  hfdcan1.Init.TxFifoQueueMode = FDCAN_TX_FIFO_OPERATION;
  if (HAL_FDCAN_Init(&hfdcan1) != HAL_OK)
  {
    Error_Handler();
  }
  /* USER CODE BEGIN FDCAN1_Init 2 */
  FDCAN1_ConfigFilterAndStart();
  /* USER CODE END FDCAN1_Init 2 */

}

static void MX_I2C3_Init(void)
{

  hi2c3.Instance = I2C3;
  hi2c3.Init.Timing = 0x30D29DE4;
  hi2c3.Init.OwnAddress1 = 0;
  hi2c3.Init.AddressingMode = I2C_ADDRESSINGMODE_7BIT;
  hi2c3.Init.DualAddressMode = I2C_DUALADDRESS_DISABLE;
  hi2c3.Init.OwnAddress2 = 0;
  hi2c3.Init.OwnAddress2Masks = I2C_OA2_NOMASK;
  hi2c3.Init.GeneralCallMode = I2C_GENERALCALL_DISABLE;
  hi2c3.Init.NoStretchMode = I2C_NOSTRETCH_DISABLE;
  if (HAL_I2C_Init(&hi2c3) != HAL_OK)
  {
    Error_Handler();
  }

  /** Configure Analogue filter
  */
  if (HAL_I2CEx_ConfigAnalogFilter(&hi2c3, I2C_ANALOGFILTER_ENABLE) != HAL_OK)
  {
    Error_Handler();
  }

  /** Configure Digital filter
  */
  if (HAL_I2CEx_ConfigDigitalFilter(&hi2c3, 0) != HAL_OK)
  {
    Error_Handler();
  }

}

static void MX_OPAMP1_Init(void)
{

  hopamp1.Instance = OPAMP1;
  hopamp1.Init.PowerMode = OPAMP_POWERMODE_NORMALSPEED;
  hopamp1.Init.Mode = OPAMP_PGA_MODE;
  hopamp1.Init.NonInvertingInput = OPAMP_NONINVERTINGINPUT_IO0;
  hopamp1.Init.InternalOutput = DISABLE;
  hopamp1.Init.TimerControlledMuxmode = OPAMP_TIMERCONTROLLEDMUXMODE_DISABLE;
  hopamp1.Init.PgaConnect = OPAMP_PGA_CONNECT_INVERTINGINPUT_IO0_BIAS;
  hopamp1.Init.PgaGain = OPAMP_PGA_GAIN_16_OR_MINUS_15;
  hopamp1.Init.UserTrimming = OPAMP_TRIMMING_FACTORY;
  if (HAL_OPAMP_Init(&hopamp1) != HAL_OK)
  {
    Error_Handler();
  }

}

static void MX_OPAMP2_Init(void)
{

  hopamp2.Instance = OPAMP2;
  hopamp2.Init.PowerMode = OPAMP_POWERMODE_NORMALSPEED;
  hopamp2.Init.Mode = OPAMP_PGA_MODE;
  hopamp2.Init.NonInvertingInput = OPAMP_NONINVERTINGINPUT_IO0;
  hopamp2.Init.InternalOutput = DISABLE;
  hopamp2.Init.TimerControlledMuxmode = OPAMP_TIMERCONTROLLEDMUXMODE_DISABLE;
  hopamp2.Init.PgaConnect = OPAMP_PGA_CONNECT_INVERTINGINPUT_IO0_BIAS;
  hopamp2.Init.PgaGain = OPAMP_PGA_GAIN_16_OR_MINUS_15;
  hopamp2.Init.UserTrimming = OPAMP_TRIMMING_FACTORY;
  if (HAL_OPAMP_Init(&hopamp2) != HAL_OK)
  {
    Error_Handler();
  }

}

static void MX_OPAMP3_Init(void)
{

  hopamp3.Instance = OPAMP3;
  hopamp3.Init.PowerMode = OPAMP_POWERMODE_NORMALSPEED;
  hopamp3.Init.Mode = OPAMP_PGA_MODE;
  hopamp3.Init.NonInvertingInput = OPAMP_NONINVERTINGINPUT_IO0;
  hopamp3.Init.InternalOutput = DISABLE;
  hopamp3.Init.TimerControlledMuxmode = OPAMP_TIMERCONTROLLEDMUXMODE_DISABLE;
  hopamp3.Init.PgaConnect = OPAMP_PGA_CONNECT_INVERTINGINPUT_IO0_BIAS;
  hopamp3.Init.PgaGain = OPAMP_PGA_GAIN_16_OR_MINUS_15;
  hopamp3.Init.UserTrimming = OPAMP_TRIMMING_FACTORY;
  if (HAL_OPAMP_Init(&hopamp3) != HAL_OK)
  {
    Error_Handler();
  }

}

static void MX_SPI1_Init(void)
{

  /* SPI1 parameter configuration*/
  hspi1.Instance = SPI1;
  hspi1.Init.Mode = SPI_MODE_MASTER;
  hspi1.Init.Direction = SPI_DIRECTION_2LINES;
  hspi1.Init.DataSize = SPI_DATASIZE_16BIT;
  hspi1.Init.CLKPolarity = SPI_POLARITY_LOW;
  hspi1.Init.CLKPhase = SPI_PHASE_2EDGE;
  hspi1.Init.NSS = SPI_NSS_SOFT;
  hspi1.Init.BaudRatePrescaler = SPI_BAUDRATEPRESCALER_32;
  hspi1.Init.FirstBit = SPI_FIRSTBIT_MSB;
  hspi1.Init.TIMode = SPI_TIMODE_DISABLE;
  hspi1.Init.CRCCalculation = SPI_CRCCALCULATION_DISABLE;
  hspi1.Init.CRCPolynomial = 7;
  hspi1.Init.CRCLength = SPI_CRC_LENGTH_DATASIZE;
  hspi1.Init.NSSPMode = SPI_NSS_PULSE_DISABLE;
  if (HAL_SPI_Init(&hspi1) != HAL_OK)
  {
    Error_Handler();
  }

}

static void MX_TIM1_Init(void)
{

  TIM_ClockConfigTypeDef sClockSourceConfig = {0};
  TIM_MasterConfigTypeDef sMasterConfig = {0};
  TIM_OC_InitTypeDef sConfigOC = {0};
  TIM_BreakDeadTimeConfigTypeDef sBreakDeadTimeConfig = {0};

  htim1.Instance = TIM1;
  htim1.Init.Prescaler = 0;
  htim1.Init.CounterMode = TIM_COUNTERMODE_CENTERALIGNED3;
  htim1.Init.Period = 3999;
  htim1.Init.ClockDivision = TIM_CLOCKDIVISION_DIV1;
  htim1.Init.RepetitionCounter = 1;
  htim1.Init.AutoReloadPreload = TIM_AUTORELOAD_PRELOAD_ENABLE;
  if (HAL_TIM_Base_Init(&htim1) != HAL_OK)
  {
    Error_Handler();
  }
  sClockSourceConfig.ClockSource = TIM_CLOCKSOURCE_INTERNAL;
  if (HAL_TIM_ConfigClockSource(&htim1, &sClockSourceConfig) != HAL_OK)
  {
    Error_Handler();
  }
  if (HAL_TIM_PWM_Init(&htim1) != HAL_OK)
  {
    Error_Handler();
  }
  sMasterConfig.MasterOutputTrigger = TIM_TRGO_UPDATE;
  sMasterConfig.MasterOutputTrigger2 = TIM_TRGO2_RESET;
  sMasterConfig.MasterSlaveMode = TIM_MASTERSLAVEMODE_DISABLE;
  if (HAL_TIMEx_MasterConfigSynchronization(&htim1, &sMasterConfig) != HAL_OK)
  {
    Error_Handler();
  }
  sConfigOC.OCMode = TIM_OCMODE_PWM2;
  sConfigOC.Pulse = 0;
  sConfigOC.OCPolarity = TIM_OCPOLARITY_HIGH;
  sConfigOC.OCNPolarity = TIM_OCNPOLARITY_HIGH;
  sConfigOC.OCFastMode = TIM_OCFAST_DISABLE;
  sConfigOC.OCIdleState = TIM_OCIDLESTATE_RESET;
  sConfigOC.OCNIdleState = TIM_OCNIDLESTATE_RESET;
  if (HAL_TIM_PWM_ConfigChannel(&htim1, &sConfigOC, TIM_CHANNEL_1) != HAL_OK)
  {
    Error_Handler();
  }
  if (HAL_TIM_PWM_ConfigChannel(&htim1, &sConfigOC, TIM_CHANNEL_2) != HAL_OK)
  {
    Error_Handler();
  }
  if (HAL_TIM_PWM_ConfigChannel(&htim1, &sConfigOC, TIM_CHANNEL_3) != HAL_OK)
  {
    Error_Handler();
  }
  sBreakDeadTimeConfig.OffStateRunMode = TIM_OSSR_DISABLE;
  sBreakDeadTimeConfig.OffStateIDLEMode = TIM_OSSI_DISABLE;
  sBreakDeadTimeConfig.LockLevel = TIM_LOCKLEVEL_OFF;
  sBreakDeadTimeConfig.DeadTime = 100;
  sBreakDeadTimeConfig.BreakState = TIM_BREAK_DISABLE;
  sBreakDeadTimeConfig.BreakPolarity = TIM_BREAKPOLARITY_HIGH;
  sBreakDeadTimeConfig.BreakFilter = 0;
  sBreakDeadTimeConfig.BreakAFMode = TIM_BREAK_AFMODE_INPUT;
  sBreakDeadTimeConfig.Break2State = TIM_BREAK2_DISABLE;
  sBreakDeadTimeConfig.Break2Polarity = TIM_BREAK2POLARITY_HIGH;
  sBreakDeadTimeConfig.Break2Filter = 0;
  sBreakDeadTimeConfig.Break2AFMode = TIM_BREAK_AFMODE_INPUT;
  sBreakDeadTimeConfig.AutomaticOutput = TIM_AUTOMATICOUTPUT_DISABLE;
  if (HAL_TIMEx_ConfigBreakDeadTime(&htim1, &sBreakDeadTimeConfig) != HAL_OK)
  {
    Error_Handler();
  }
  HAL_TIM_MspPostInit(&htim1);

}

static void MX_TIM2_Init(void)
{

  TIM_ClockConfigTypeDef sClockSourceConfig = {0};
  TIM_MasterConfigTypeDef sMasterConfig = {0};

  htim2.Instance = TIM2;
  htim2.Init.Prescaler = 159;
  htim2.Init.CounterMode = TIM_COUNTERMODE_UP;
  htim2.Init.Period = 199;
  htim2.Init.ClockDivision = TIM_CLOCKDIVISION_DIV1;
  htim2.Init.AutoReloadPreload = TIM_AUTORELOAD_PRELOAD_DISABLE;
  if (HAL_TIM_Base_Init(&htim2) != HAL_OK)
  {
    Error_Handler();
  }
  sClockSourceConfig.ClockSource = TIM_CLOCKSOURCE_INTERNAL;
  if (HAL_TIM_ConfigClockSource(&htim2, &sClockSourceConfig) != HAL_OK)
  {
    Error_Handler();
  }
  sMasterConfig.MasterOutputTrigger = TIM_TRGO_RESET;
  sMasterConfig.MasterSlaveMode = TIM_MASTERSLAVEMODE_DISABLE;
  if (HAL_TIMEx_MasterConfigSynchronization(&htim2, &sMasterConfig) != HAL_OK)
  {
    Error_Handler();
  }

}

static void MX_TIM3_Init(void)
{

  TIM_Encoder_InitTypeDef sConfig = {0};
  TIM_MasterConfigTypeDef sMasterConfig = {0};

  htim3.Instance = TIM3;
  htim3.Init.Prescaler = 0;
  htim3.Init.CounterMode = TIM_COUNTERMODE_UP;
  htim3.Init.Period = 65535;
  htim3.Init.ClockDivision = TIM_CLOCKDIVISION_DIV1;
  htim3.Init.AutoReloadPreload = TIM_AUTORELOAD_PRELOAD_DISABLE;
  sConfig.EncoderMode = TIM_ENCODERMODE_TI12;
  sConfig.IC1Polarity = TIM_ICPOLARITY_RISING;
  sConfig.IC1Selection = TIM_ICSELECTION_DIRECTTI;
  sConfig.IC1Prescaler = TIM_ICPSC_DIV1;
  sConfig.IC1Filter = 0;
  sConfig.IC2Polarity = TIM_ICPOLARITY_RISING;
  sConfig.IC2Selection = TIM_ICSELECTION_DIRECTTI;
  sConfig.IC2Prescaler = TIM_ICPSC_DIV1;
  sConfig.IC2Filter = 0;
  if (HAL_TIM_Encoder_Init(&htim3, &sConfig) != HAL_OK)
  {
    Error_Handler();
  }
  sMasterConfig.MasterOutputTrigger = TIM_TRGO_RESET;
  sMasterConfig.MasterSlaveMode = TIM_MASTERSLAVEMODE_DISABLE;
  if (HAL_TIMEx_MasterConfigSynchronization(&htim3, &sMasterConfig) != HAL_OK)
  {
    Error_Handler();
  }

}

static void MX_TIM8_Init(void)
{

  TIM_ClockConfigTypeDef sClockSourceConfig = {0};
  TIM_MasterConfigTypeDef sMasterConfig = {0};

  htim8.Instance = TIM8;
  htim8.Init.Prescaler = 0;
  htim8.Init.CounterMode = TIM_COUNTERMODE_UP;
  htim8.Init.Period = 64;
  htim8.Init.ClockDivision = TIM_CLOCKDIVISION_DIV1;
  htim8.Init.RepetitionCounter = 0;
  htim8.Init.AutoReloadPreload = TIM_AUTORELOAD_PRELOAD_DISABLE;
  if (HAL_TIM_Base_Init(&htim8) != HAL_OK)
  {
    Error_Handler();
  }
  sClockSourceConfig.ClockSource = TIM_CLOCKSOURCE_INTERNAL;
  if (HAL_TIM_ConfigClockSource(&htim8, &sClockSourceConfig) != HAL_OK)
  {
    Error_Handler();
  }
  if (HAL_TIM_OnePulse_Init(&htim8, TIM_OPMODE_SINGLE) != HAL_OK)
  {
    Error_Handler();
  }
  sMasterConfig.MasterOutputTrigger = TIM_TRGO_RESET;
  sMasterConfig.MasterOutputTrigger2 = TIM_TRGO2_RESET;
  sMasterConfig.MasterSlaveMode = TIM_MASTERSLAVEMODE_DISABLE;
  if (HAL_TIMEx_MasterConfigSynchronization(&htim8, &sMasterConfig) != HAL_OK)
  {
    Error_Handler();
  }

}

static void MX_TIM16_Init(void)
{

  htim16.Instance = TIM16;
  htim16.Init.Prescaler = 99;
  htim16.Init.CounterMode = TIM_COUNTERMODE_UP;
  htim16.Init.Period = 15999;
  htim16.Init.ClockDivision = TIM_CLOCKDIVISION_DIV1;
  htim16.Init.RepetitionCounter = 0;
  htim16.Init.AutoReloadPreload = TIM_AUTORELOAD_PRELOAD_DISABLE;
  if (HAL_TIM_Base_Init(&htim16) != HAL_OK)
  {
    Error_Handler();
  }

}

static void MX_TIM17_Init(void)
{

  TIM_OC_InitTypeDef sConfigOC = {0};
  TIM_BreakDeadTimeConfigTypeDef sBreakDeadTimeConfig = {0};

  htim17.Instance = TIM17;
  htim17.Init.Prescaler = 159;
  htim17.Init.CounterMode = TIM_COUNTERMODE_UP;
  htim17.Init.Period = 65535;
  htim17.Init.ClockDivision = TIM_CLOCKDIVISION_DIV1;
  htim17.Init.RepetitionCounter = 0;
  htim17.Init.AutoReloadPreload = TIM_AUTORELOAD_PRELOAD_DISABLE;
  if (HAL_TIM_Base_Init(&htim17) != HAL_OK)
  {
    Error_Handler();
  }
  if (HAL_TIM_PWM_Init(&htim17) != HAL_OK)
  {
    Error_Handler();
  }
  sConfigOC.OCMode = TIM_OCMODE_PWM1;
  sConfigOC.Pulse = 0;
  sConfigOC.OCPolarity = TIM_OCPOLARITY_HIGH;
  sConfigOC.OCNPolarity = TIM_OCNPOLARITY_HIGH;
  sConfigOC.OCFastMode = TIM_OCFAST_DISABLE;
  sConfigOC.OCIdleState = TIM_OCIDLESTATE_RESET;
  sConfigOC.OCNIdleState = TIM_OCNIDLESTATE_RESET;
  if (HAL_TIM_PWM_ConfigChannel(&htim17, &sConfigOC, TIM_CHANNEL_1) != HAL_OK)
  {
    Error_Handler();
  }
  sBreakDeadTimeConfig.OffStateRunMode = TIM_OSSR_DISABLE;
  sBreakDeadTimeConfig.OffStateIDLEMode = TIM_OSSI_DISABLE;
  sBreakDeadTimeConfig.LockLevel = TIM_LOCKLEVEL_OFF;
  sBreakDeadTimeConfig.DeadTime = 0;
  sBreakDeadTimeConfig.BreakState = TIM_BREAK_DISABLE;
  sBreakDeadTimeConfig.BreakPolarity = TIM_BREAKPOLARITY_HIGH;
  sBreakDeadTimeConfig.BreakFilter = 0;
  sBreakDeadTimeConfig.AutomaticOutput = TIM_AUTOMATICOUTPUT_DISABLE;
  if (HAL_TIMEx_ConfigBreakDeadTime(&htim17, &sBreakDeadTimeConfig) != HAL_OK)
  {
    Error_Handler();
  }
  HAL_TIM_MspPostInit(&htim17);

}

static void MX_USART1_UART_Init(void)
{

  huart1.Instance = USART1;
  huart1.Init.BaudRate = 115200;
  huart1.Init.WordLength = UART_WORDLENGTH_8B;
  huart1.Init.StopBits = UART_STOPBITS_1;
  huart1.Init.Parity = UART_PARITY_NONE;
  huart1.Init.Mode = UART_MODE_TX_RX;
  huart1.Init.HwFlowCtl = UART_HWCONTROL_NONE;
  huart1.Init.OverSampling = UART_OVERSAMPLING_16;
  huart1.Init.OneBitSampling = UART_ONE_BIT_SAMPLE_DISABLE;
  huart1.Init.ClockPrescaler = UART_PRESCALER_DIV1;
  huart1.AdvancedInit.AdvFeatureInit = UART_ADVFEATURE_NO_INIT;
  if (HAL_UART_Init(&huart1) != HAL_OK)
  {
    Error_Handler();
  }
  if (HAL_UARTEx_SetTxFifoThreshold(&huart1, UART_TXFIFO_THRESHOLD_1_8) != HAL_OK)
  {
    Error_Handler();
  }
  if (HAL_UARTEx_SetRxFifoThreshold(&huart1, UART_RXFIFO_THRESHOLD_1_8) != HAL_OK)
  {
    Error_Handler();
  }
  if (HAL_UARTEx_DisableFifoMode(&huart1) != HAL_OK)
  {
    Error_Handler();
  }

}

static void MX_DMA_Init(void)
{

  /* DMA controller clock enable */
  __HAL_RCC_DMAMUX1_CLK_ENABLE();
  __HAL_RCC_DMA1_CLK_ENABLE();

  /* DMA interrupt init */
  /* DMA1_Channel2_IRQn interrupt configuration */
  HAL_NVIC_SetPriority(DMA1_Channel2_IRQn, 0, 0);
  HAL_NVIC_EnableIRQ(DMA1_Channel2_IRQn);

}

static void MX_GPIO_Init(void)
{
  GPIO_InitTypeDef GPIO_InitStruct = {0};

  /* GPIO Ports Clock Enable */
  __HAL_RCC_GPIOC_CLK_ENABLE();
  __HAL_RCC_GPIOF_CLK_ENABLE();
  __HAL_RCC_GPIOA_CLK_ENABLE();
  __HAL_RCC_GPIOB_CLK_ENABLE();
  __HAL_RCC_GPIOE_CLK_ENABLE();

  /*Configure GPIO pin Output Level */
  HAL_GPIO_WritePin(WAKE_GPIO_Port, WAKE_Pin, GPIO_PIN_RESET);

  /*Configure GPIO pin Output Level */
  HAL_GPIO_WritePin(SPI1_SS_GPIO_Port, SPI1_SS_Pin, GPIO_PIN_RESET);

  /*Configure GPIO pin Output Level */
  HAL_GPIO_WritePin(PWM_LED_GPIO_Port, PWM_LED_Pin, GPIO_PIN_RESET);

  /*Configure GPIO pin : USER_SW_Pin */
  GPIO_InitStruct.Pin = USER_SW_Pin;
  GPIO_InitStruct.Mode = GPIO_MODE_IT_FALLING;
  GPIO_InitStruct.Pull = GPIO_NOPULL;
  HAL_GPIO_Init(USER_SW_GPIO_Port, &GPIO_InitStruct);

  /*Configure GPIO pin : k_Pin */
  GPIO_InitStruct.Pin = k_Pin;
  GPIO_InitStruct.Mode = GPIO_MODE_INPUT;
  GPIO_InitStruct.Pull = GPIO_NOPULL;
  HAL_GPIO_Init(k_GPIO_Port, &GPIO_InitStruct);

  /*Configure GPIO pin : WAKE_Pin */
  GPIO_InitStruct.Pin = WAKE_Pin;
  GPIO_InitStruct.Mode = GPIO_MODE_OUTPUT_PP;
  GPIO_InitStruct.Pull = GPIO_NOPULL;
  GPIO_InitStruct.Speed = GPIO_SPEED_FREQ_LOW;
  HAL_GPIO_Init(WAKE_GPIO_Port, &GPIO_InitStruct);

  /*Configure GPIO pin : SPI1_SS_Pin */
  GPIO_InitStruct.Pin = SPI1_SS_Pin;
  GPIO_InitStruct.Mode = GPIO_MODE_OUTPUT_PP;
  GPIO_InitStruct.Pull = GPIO_NOPULL;
  GPIO_InitStruct.Speed = GPIO_SPEED_FREQ_VERY_HIGH;
  HAL_GPIO_Init(SPI1_SS_GPIO_Port, &GPIO_InitStruct);

  /*Configure GPIO pin : PWM_LED_Pin */
  GPIO_InitStruct.Pin = PWM_LED_Pin;
  GPIO_InitStruct.Mode = GPIO_MODE_OUTPUT_PP;
  GPIO_InitStruct.Pull = GPIO_NOPULL;
  GPIO_InitStruct.Speed = GPIO_SPEED_FREQ_LOW;
  HAL_GPIO_Init(PWM_LED_GPIO_Port, &GPIO_InitStruct);

  /* EXTI interrupt init*/
  HAL_NVIC_SetPriority(EXTI15_10_IRQn, 0, 0);
  HAL_NVIC_EnableIRQ(EXTI15_10_IRQn);

}

void Error_Handler(void)
{
  __disable_irq();
  while (1)
  {
  }
}
